# SN32F700 register map
Vendor: SONiX Technology Co., Ltd.; Series: SN32F700; File version: 1.9
ARM 32-bit Cortex-M0 Microcontroller based device, CPU clock up to 50MHz, etc.
CPU: CM0 r0p0, little endian, no MPU, no FPU, 2 interrupt priority bits
Registers are 32-bit, read-write, reset 0x0 unless marked. A register's access mark holds for its fields unless they carry their own. Offsets are from the block's base; lines under a group give offsets from that group; [hi:lo] are bit positions; {n}, {i} and the like mark numbered series; 'fields as' and 'values as' point back to an identical list; <NAME> marks a mode.

## Memory map
0x1FFF221C SN_UC size 0x2000 — UC Registers
0x40000000 SN_CT16B0 size 0x2000 — 16-bit Timer 0 with Capture function
0x40002000 SN_CT16B1 size 0x2000
0x40004000 SN_CT32B0 size 0x2000 — 32-bit Timer 0 with Capture function
0x40006000 SN_CT32B1 size 0x2000
0x40010000 SN_WDT size 0x2000 — Watchdog Timer
0x40012000 SN_RTC size 0x2000 — Real-time Clock
0x40016000 SN_USART0 size 0x2000 — USART0
0x40018000 SN_I2C0 size 0x2000 — I2C0
0x4001A000 SN_I2S size 0x2000 — I2S
0x4001C000 SN_SSP0 size 0x2000 — SSP0
0x40026000 SN_ADC size 0x2000 — ADC
0x40032000 SN_PMU size 0x2000 — Power Management Unit
0x40044000 SN_GPIO0 size 0x2000 — General Purpose I/O
0x40046000 SN_GPIO1 size 0x2000
0x40048000 SN_GPIO2 size 0x2000
0x4004A000 SN_GPIO3 size 0x2000
0x40056000 SN_USART1 size 0x2000
0x40058000 SN_SSP1 size 0x2000
0x4005A000 SN_I2C1 size 0x2000
0x4005E000 SN_SYS1 size 0x2000 — System Control Registers
0x40060000 SN_SYS0 size 0x2000 — System Control Registers
0x40062000 SN_FLASH size 0x2000 — FLASH Memory Control Registers

## Interrupts
0 WAKEUP (SN_PMU)
13 SSP0 (SN_SSP0)
14 SSP1 (SN_SSP1)
15 I2C0 (SN_I2C0)
16 CT16B0 (SN_CT16B0)
17 CT16B1 (SN_CT16B1)
18 CT32B0 (SN_CT32B0)
19 CT32B1 (SN_CT32B1)
20 I2S (SN_I2S)
21 USART0 (SN_USART0)
22 USART1 (SN_USART1)
23 I2C1 (SN_I2C1)
24 ADC (SN_ADC)
25 WDT (SN_WDT)
26 LVD (SN_SYS0)
27 RTC (SN_RTC)
28 P3 (SN_GPIO3)
29 P2 (SN_GPIO2)
30 P1 (SN_GPIO1)
31 P0 (SN_GPIO0)

## SN_SYS0 — System Control Registers
Base 0x40060000
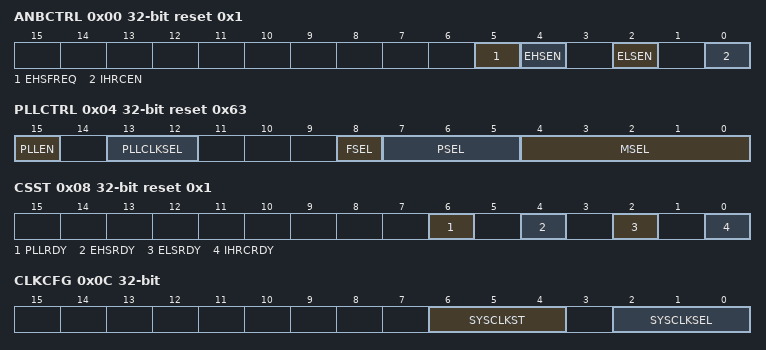
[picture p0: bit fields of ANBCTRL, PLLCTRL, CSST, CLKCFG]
0x00 ANBCTRL reset 0x1 — Offset:0x00 Analog Block Control Register
  [5] EHSFREQ — EHS XTAL frequency range
    0=Low (Less equal than 12MHz); 1=High (Greater than 12MHz)
  [4] EHSEN — EHS XTAL enable
    0=Disable EHS Xtal; 1=Enable EHS Xtal
  [2] ELSEN — ELS XTAL enable
    0=Disable ELS Xtal; 1=Enable ELS Xtal
  [0] IHRCEN — IHRC enable
    0=Disable IHRC; 1=Enable IHRC
0x04 PLLCTRL reset 0x63 — Offset:0x04 PLL Control Register
  [15] PLLEN — PLL enable
    0=Disable PLL; 1=Enable PLL
  [13:12] PLLCLKSEL — PLL clock source
    0=IHRC (12MHz); 1=EHS XTAL (10MHz~25MHz)
  [8] FSEL — F=POWER(2, FSEL)
    0=F=1; 1=F=2
  [7:5] PSEL — P=PSEL*2
    3=011b (P=6); 4=100b (P=8); 5=101b (P=10); 6=110b (P=12); 7=111b (P=14)
  [4:0] MSEL — M: 3~31
0x08 CSST ro reset 0x1 — Offset:0x08 Clock Source Status Register
  [6] PLLRDY — PLL ready flag
    0=PLL is Not locked; 1=PLL is locked
  [4] EHSRDY — EHS XTAL ready flag
    0=EHS Xtal is Not Ready; 1=EHS Xtal is Ready
  [2] ELSRDY — ELS XTAL ready flag
    0=ELS Xtal is Not Ready; 1=ELS Xtal is Ready
  [0] IHRCRDY — IHRC ready flag
    0=IHRC is Not Ready; 1=IHRC is Ready
0x0C CLKCFG — Offset:0x0C System Clock Configuration Register
  [6:4] SYSCLKST ro — System clock switch status
    0=IHRC (IHRC is used as system clock); 1=ILRC (ILRC is used as system clock); 2=EHS XTAL (EHS XTAL is used as system clock); 3=ELS XTAL (ELS XTAL is used as system clock); 4=PLL (PLL output is used as system clock)
  [2:0] SYSCLKSEL — System clock source selection
    0=IHRC (IHRC is system clock); 1=ILRC (ILRC is system clock); 2=EHS XTAL (EHS Xtal is system clock); 3=ELS XTAL (ELS Xtal is system clock); 4=PLL Output (PLL is system clock)
0x10 AHBCP — Offset:0x10 AHB Clock Prescale Register
  [3:0] AHBPRE — AHB clock source prescaler
    0=0000b (FAHB=FSYSCLK/1); 1=0001b (FAHB=FSYSCLK/2); 2=0010b (FAHB=FSYSCLK/4); 3=0011b (FAHB=FSYSCLK/8); 4=0100b (FAHB=FSYSCLK/16); 5=0101b (FAHB=FSYSCLK/32); 6=0110b (FAHB=FSYSCLK/64); 7=0111b (FAHB=FSYSCLK/128); 8=1000b (FAHB=FSYSCLK/256); 9=1001b (FAHB=FSYSCLK/512)
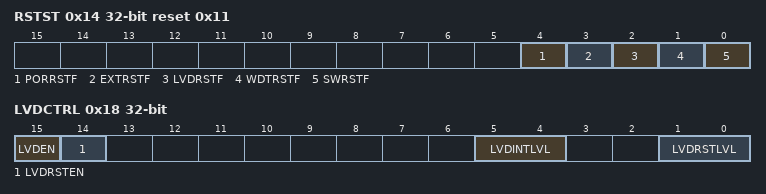
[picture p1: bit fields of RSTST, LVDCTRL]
0x14 RSTST reset 0x11 — Offset:0x14 System Reset Status Register
  [4] PORRSTF — POR reset flag
    0=No POR occurred; 1=POR occurred
  [3] EXTRSTF — External reset flag
    0=No Extenral reset occurred; 1=External reset occurred
  [2] LVDRSTF — LVD reset flag
    0=No LVD reset occurred; 1=LVD reset occurred
  [1] WDTRSTF — WDT reset flag
    0=No WDT reset occurred; 1=WDT reset occurred
  [0] SWRSTF — Software reset flag
    0=No SW reset occurred; 1=SW reset occurred
0x18 LVDCTRL — Offset:0x18 LVD Control Register
  [15] LVDEN — LVD enable
    0=Diable (Disable LVD); 1=Enable LVD
  [14] LVDRSTEN — LVD Reset enable
    0=Diable (Disable LVD reset); 1=Enable LVD reset
  [5:4] LVDINTLVL — LVD interrupt level
    0=2.00V (LVD interrupt threshold is 2.00V); 1=2.70V (LVD interrupt threshold is 2.70V); 2=3.00V (LVD interrupt threshold is 3.00V)
  [1:0] LVDRSTLVL — LVD reset level
    0=2.40V (LVD reset threshold is 2.40V); 1=2.70V (LVD reset threshold is 2.70V); 2=2.00V (LVD reset threshold is 2.00V)
0x1C EXRSTCTRL — Offset:0x1C External Reset Pin Control Register
  [0] RESETDIS — External reset pin disable
    0=Enable (P3.6 acts as External Reset pin); 1=Disable (P3.6 acts as GPIO pin)
0x20 SWDCTRL — Offset:0x20 SWD Pin Control Register
  [0] SWDDIS — SWD pin disable
    0=Enable SWD pins; 1=Disable SWD pins

## Licence text in the file
ARM Limited (ARM) is supplying this software for use with Cortex-M processor based microcontroller, but can be equally used for other suitable processor architectures. This file can be freely distributed. Modifications to this file shall be clearly marked. . THIS SOFTWARE IS PROVIDED "AS IS". NO WARRANTIES, WHETHER EXPRESS, IMPLIED. OR STATUTORY, INCLUDING, BUT NOT LIMITED TO, IMPLIED WARRANTIES OF. MERCHANTABILITY AND FITNESS FOR A PARTICULAR PURPOSE APPLY TO THIS SOFTWARE. ARM SHALL NOT, IN ANY CIRCUMSTANCES, BE LIABLE FOR SPECIAL, INCIDENTAL, OR. CONSEQUENTIAL DAMAGES, FOR ANY REASON WHATSOEVER.

## Notices in the file
Copyright (C) 2019 ARM Limited. All rights reserved.
